# nrf52840 register map
Vendor: Nordic Semiconductor; Series: nrf52; File version: 1
CPU: CM4 r0p1, little endian, MPU, FPU, 3 interrupt priority bits
Registers are 32-bit, read-write, reset 0x0 unless marked. A register's access mark holds for its fields unless they carry their own. Offsets are from the block's base; [hi:lo] are bit positions; lines under a group give offsets from that group; {n}, {i} and the like mark numbered series.

## EGU0 — Event Generator Unit 0
Base 0x40014000
Same registers: EGU1 0x40015000, EGU2 0x40016000, EGU3 0x40017000, EGU4 0x40018000, EGU5 0x40019000
{0x0+4i} TASKS_TRIGGER[{i}] (i=0..15) wo — Description collection: Trigger n for triggering the corresponding TRIGGERED[n] event
  [0] TASKS_TRIGGER — Trigger n for triggering the corresponding TRIGGERED[n] event
    1=Trigger task
{0x100+4i} EVENTS_TRIGGERED[{i}] (i=0..15) — Description collection: Event number n generated by triggering the corresponding TRIGGER[n] task
  [0] EVENTS_TRIGGERED — Event number n generated by triggering the corresponding TRIGGER[n] task
    0=NotGenerated (Event not generated); 1=Generated (Event generated)
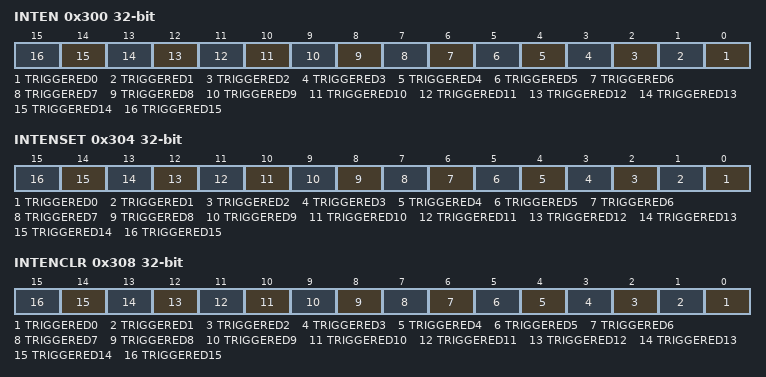
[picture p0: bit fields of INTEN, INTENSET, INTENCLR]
0x300 INTEN — Enable or disable interrupt
  [all] fields
    0=Disabled; 1=Enabled
  [n] TRIGGERED{n} (n=0..15) — Enable or disable interrupt for event TRIGGERED[{n}]
0x304 INTENSET — Enable interrupt
  [all] fields
    on read: 0=Disabled (Read: Disabled); 1=Enabled (Read: Enabled) | on write: 1=Set (Enable)
  [n] TRIGGERED{n} (n=0..15) — Write '1' to enable interrupt for event TRIGGERED[{n}]
0x308 INTENCLR — Disable interrupt
  [all] fields
    on read: 0=Disabled (Read: Disabled); 1=Enabled (Read: Enabled) | on write: 1=Clear (Disable)
  [n] TRIGGERED{n} (n=0..15) — Write '1' to disable interrupt for event TRIGGERED[{n}]

## SWI0 — Software interrupt 0
Base 0x40014000; alternate view of EGU0
Same registers: SWI1 0x40015000 (alternate view of EGU1), SWI2 0x40016000 (alternate view of EGU2), SWI3 0x40017000 (alternate view of EGU3), SWI4 0x40018000 (alternate view of EGU4), SWI5 0x40019000 (alternate view of EGU5)

## ACL — Access control lists
Base 0x4001E000
{0x800+0x10*i} ACL[{i}] (i=0..7) group — Unspecified
  0x00 ADDR rw-once — Description cluster: Configure the word-aligned start address of region n to protect
    [31:0] ADDR — Valid word-aligned start address of region n to protect. Address must point to a flash page boundary.
  0x04 SIZE rw-once — Description cluster: Size of region to protect counting from address ACL[n].ADDR. Write '0' as no effect.
    [31:0] SIZE — Size of flash region n in bytes. Must be a multiple of the flash page size, and the maximum region size is limited to 512kB.
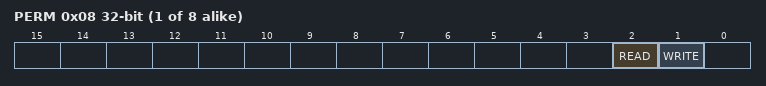
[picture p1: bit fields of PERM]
  0x08 PERM rw-once — Description cluster: Access permissions for region n as defined by start address ACL[n].ADDR and size ACL[n].SIZE
    [2] READ — Configure read permissions for region n. Write '0' has no effect.
      0=Enable (Allow read instructions to region n); 1=Disable (Block read instructions to region n)
    [1] WRITE — Configure write and erase permissions for region n. Write '0' has no effect.
      0=Enable (Allow write and erase instructions to region n); 1=Disable (Block write and erase instructions to region n)

## NVMC — Non Volatile Memory Controller
Base 0x4001E000; alternate view of ACL
0x400 READY ro reset 0x1 — Ready flag
  [0] READY — NVMC is ready or busy
    0=Busy (NVMC is busy (on-going write or erase operation)); 1=Ready (NVMC is ready)
0x408 READYNEXT ro — Ready flag
  [0] READYNEXT — NVMC can accept a new write operation
    0=Busy (NVMC cannot accept any write operation); 1=Ready (NVMC is ready)
0x504 CONFIG — Configuration register
  [1:0] WEN — Program memory access mode. It is strongly recommended to only activate erase and write modes when they are actively used. Enabling write or erase will invalidate the cache and keep it invalidated.
    0=Ren (Read only access); 1=Wen (Write enabled); 2=Een (Erase enabled)
0x508 ERASEPAGE — Register for erasing a page in code area
  [31:0] ERASEPAGE — Register for starting erase of a page in code area
0x508 ERASEPCR1 (alternate view of ERASEPAGE) — Deprecated register - Register for erasing a page in code area. Equivalent to ERASEPAGE.
  [31:0] ERASEPCR1 — Register for erasing a page in code area. Equivalent to ERASEPAGE.
0x50C ERASEALL — Register for erasing all non-volatile user memory
  [0] ERASEALL — Erase all non-volatile memory including UICR registers. Note that the erase must be enabled using CONFIG.WEN before the non-volatile memory can be erased.
    0=NoOperation; 1=Erase (Start chip erase)
0x510 ERASEPCR0 — Deprecated register - Register for erasing a page in code area. Equivalent to ERASEPAGE.
  [31:0] ERASEPCR0 — Register for starting erase of a page in code area. Equivalent to ERASEPAGE.
0x514 ERASEUICR — Register for erasing user information configuration registers
  [0] ERASEUICR — Register starting erase of all user information configuration registers. Note that the erase must be enabled using CONFIG.WEN before the UICR can be erased.
    0=NoOperation; 1=Erase (Start erase of UICR)
0x518 ERASEPAGEPARTIAL — Register for partial erase of a page in code area
  [31:0] ERASEPAGEPARTIAL — Register for starting partial erase of a page in code area
0x51C ERASEPAGEPARTIALCFG reset 0xA — Register for partial erase configuration
  [6:0] DURATION — Duration of the partial erase in milliseconds
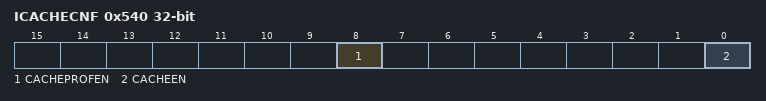
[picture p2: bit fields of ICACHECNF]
0x540 ICACHECNF — I-code cache configuration register.
  [8] CACHEPROFEN — Cache profiling enable
    0=Disabled (Disable cache profiling); 1=Enabled (Enable cache profiling)
  [0] CACHEEN — Cache enable
    0=Disabled (Disable cache. Invalidates all cache entries.); 1=Enabled (Enable cache)
0x548 IHIT — I-code cache hit counter.
  [31:0] HITS — Number of cache hits
0x54C IMISS — I-code cache miss counter.
  [31:0] MISSES — Number of cache misses
